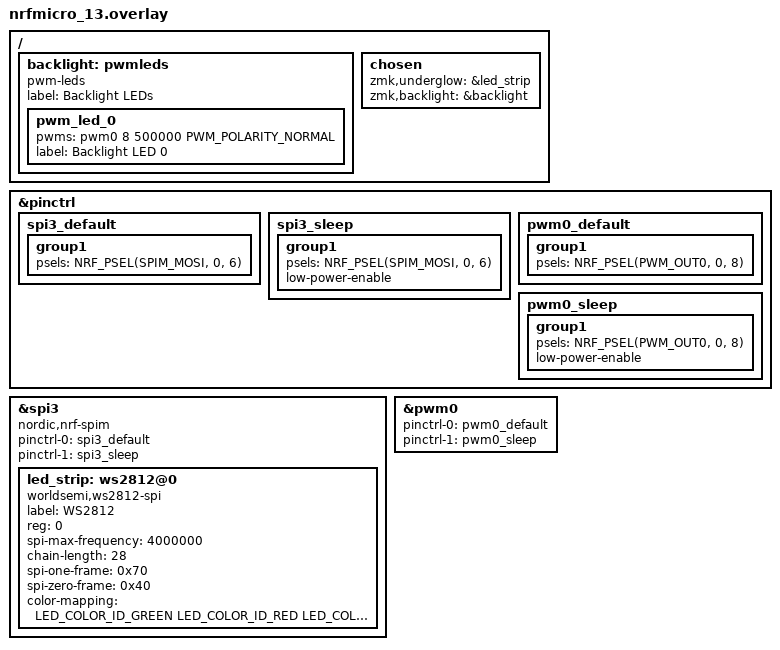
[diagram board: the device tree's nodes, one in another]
#include <dt-bindings/led/led.h>

&pinctrl {
    spi3_default: spi3_default {
        group1 {
            psels = <NRF_PSEL(SPIM_MOSI, 0, 6)>;
        };
    };

    spi3_sleep: spi3_sleep {
        group1 {
            psels = <NRF_PSEL(SPIM_MOSI, 0, 6)>;
            low-power-enable;
        };
    };

    pwm0_default: pwm0_default {
        group1 {
            psels = <NRF_PSEL(PWM_OUT0, 0, 8)>;
        };
    };

    pwm0_sleep: pwm0_sleep {
        group1 {
            psels = <NRF_PSEL(PWM_OUT0, 0, 8)>;
            low-power-enable;
        };
    };
};

&spi3 {
    compatible = "nordic,nrf-spim";
    status = "okay";

    pinctrl-0 = <&spi3_default>;
    pinctrl-1 = <&spi3_sleep>;
    pinctrl-names = "default", "sleep";

    led_strip: ws2812@0 {
        compatible = "worldsemi,ws2812-spi";
        label = "WS2812";

        /* SPI */
        reg = <0>; /* ignored, but necessary for SPI bindings */
        spi-max-frequency = <4000000>;

        /* WS2812 */
        chain-length = <28>; /* arbitrary; change at will */
        spi-one-frame = <0x70>;
        spi-zero-frame = <0x40>;

        color-mapping = <LED_COLOR_ID_GREEN LED_COLOR_ID_RED LED_COLOR_ID_BLUE>;
    };
};

&pwm0 {
    status = "okay";
    pinctrl-0 = <&pwm0_default>;
    pinctrl-1 = <&pwm0_sleep>;
    pinctrl-names = "default", "sleep";
};

/ {
    backlight: pwmleds {
        compatible = "pwm-leds";
        label = "Backlight LEDs";
        pwm_led_0 {
            pwms = <&pwm0 8 500000 PWM_POLARITY_NORMAL>;
            label = "Backlight LED 0";
        };
    };
};

/ {
    chosen {
        zmk,underglow = &led_strip;
        zmk,backlight = &backlight;
    };
};
